# CONTROLSS_CTRL_CONTROLSS_CTRL register map
Vendor: Texas Instruments
Peripheral module from a debugger description file (folder AM263).
Registers are 8-bit, read-write, reset 0x0 unless marked. A register's access mark holds for its fields unless they carry their own. Offsets are as the file gives them; lines under a group give offsets from that group; [hi:lo] are bit positions; {n}, {i} and the like mark numbered series; 'fields as' and 'values as' point back to an identical list; <NAME> marks a mode.

## CONTROLSS_CTRL_CONTROLSS_CTRL
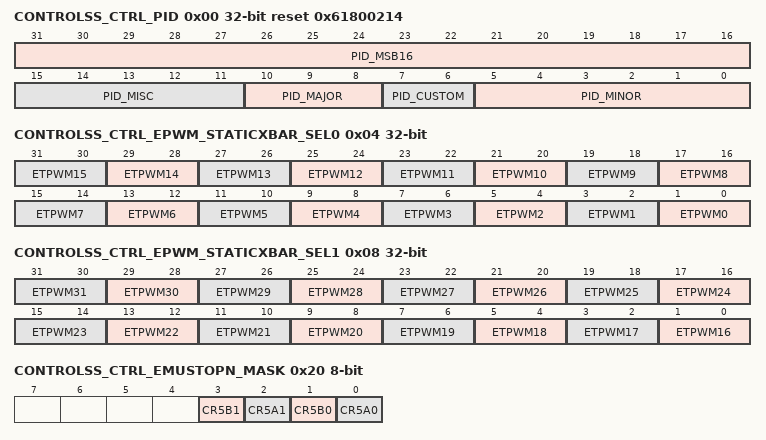
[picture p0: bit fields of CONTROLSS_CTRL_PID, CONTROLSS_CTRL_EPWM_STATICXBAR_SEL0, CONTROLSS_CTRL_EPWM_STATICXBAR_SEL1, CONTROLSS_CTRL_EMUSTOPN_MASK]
0x00 CONTROLSS_CTRL_PID 32-bit ro reset 0x61800214
  [31:16] PID_MSB16 — Not Defined
  [15:11] PID_MISC — Not Defined
  [10:8] PID_MAJOR — Not Defined
  [7:6] PID_CUSTOM — Not Defined
  [5:0] PID_MINOR — Not Defined
0x04 CONTROLSS_CTRL_EPWM_STATICXBAR_SEL0 32-bit
  [2n+1:2n] ETPWM{n} (n=0..15) — ETPWM{n} access from PCR grouping - 00 = G0, 01 = G1, 01 = G2, 11 = G3
0x08 CONTROLSS_CTRL_EPWM_STATICXBAR_SEL1 32-bit
  [2n-31:2n-32] ETPWM{n} (n=16..31) — ETPWM{n} access from PCR grouping - 00 = G0, 01 = G1, 01 = G2, 11 = G3
0x10 CONTROLSS_CTRL_EPWM_CLKSYNC 32-bit
  [31:0] BIT — ETPWM clock sync for each EPWM instance1: will allow CLK SYNC when GBCLKSYNC is written in0: No CLK SYNC when GBCLKSYNC is written in
0x18 CONTROLSS_CTRL_SDFM1_CLK0_SEL size not given
  [0] SEL — SDFM1 clock CK0 select0: source is SDFM1 CK0 from Pinmux1: source is SDFM0 CK0 from Pinmux
0x20 CONTROLSS_CTRL_EMUSTOPN_MASK
  [3] CR5B1 — Bit-mask for debug suspend cpu cores to EPWM0: CR5B1 enabled to control EMUSTOPn1: CR5B1 disabled to control EMUSTOPn
  [2] CR5A1 — Bit-mask for debug suspend cpu cores to EPWM0: CR5A1 enabled to control EMUSTOPn1: CR5A1 disabled to control EMUSTOPn
  [1] CR5B0 — Bit-mask for debug suspend cpu cores to EPWM0: CR5B0 enabled to control EMUSTOPn1: CR5B0 disabled to control EMUSTOPn
  [0] CR5A0 — Bit-mask for debug suspend cpu cores to EPWM0: CR5A0 enabled to control EMUSTOPn1: CR5A0 disabled to control EMUSTOPn
0x28 CONTROLSS_CTRL_CLB_AQ_EN0 32-bit
  [31:0] ENABLE — Enable ICCS control to CLB_AQ signal of PWM[15:0]
0x30 CONTROLSS_CTRL_CLB_AQ_EN1 32-bit
  [31:0] ENABLE — Enable ICCS control to CLB_AQ signal of PWM[31:16]
0x38 CONTROLSS_CTRL_CLB_DB_EN0 32-bit
  [31:0] ENABLE — Enable ICCS control to CLB_DB signal of PWM[15:0]
0x40 CONTROLSS_CTRL_CLB_DB_EN1 32-bit
  [31:0] ENABLE — Enable ICCS control to CLB_DB signal of PWM[31:16]
{0x100+4i} CONTROLSS_CTRL_ETPWM{i}_CLK_GATE (i=0..31)
  [2:0] CLK_GATE — writing '111' will gate clock for corresponding etpwm
{0x180+4i} CONTROLSS_CTRL_FSI_TX{i}_CLK_GATE (i=0..3)
  [2:0] CLK_GATE — writing '111' will gate clock for corresponding fsi_tx
{0x190+4i} CONTROLSS_CTRL_FSI_RX{i}_CLK_GATE (i=0..3)
  [2:0] CLK_GATE — writing '111' will gate clock for corresponding fsi_rx
{0x1A0+4i} CONTROLSS_CTRL_CMPSSA{i}_CLK_GATE (i=0..9)
  [2:0] CLK_GATE — writing '111' will gate clock for corresponding cmpss12b
{0x1D0+4i} CONTROLSS_CTRL_CMPSSB{i}_CLK_GATE (i=0..9)
  [2:0] CLK_GATE — writing '111' will gate clock for corresponding cmpss8b
{0x200+4i} CONTROLSS_CTRL_ECAP{i}_CLK_GATE (i=0..9)
  [2:0] CLK_GATE — writing '111' will gate clock for corresponding ecap
{0x240+4i} CONTROLSS_CTRL_EQEP{i}_CLK_GATE (i=0..2)
  [2:0] CLK_GATE — writing '111' will gate clock for corresponding eqep
0x250 CONTROLSS_CTRL_SDFM0_CLK_GATE
  [2:0] CLK_GATE — writing '111' will gate clock for corresponding sdfm
0x254 CONTROLSS_CTRL_SDFM1_CLK_GATE
  fields as CONTROLSS_CTRL_SDFM0_CLK_GATE
0x258 CONTROLSS_CTRL_DAC_CLK_GATE
  [2:0] CLK_GATE — writing '111' will gate clock for dac
{0x25C+4i} CONTROLSS_CTRL_ADC{i}_CLK_GATE (i=0..4)
  [2:0] CLK_GATE — writing '111' will gate clock for corresponding adc
{0x270+4i} CONTROLSS_CTRL_OTTO{i}_CLK_GATE (i=0..3)
  [2:0] CLK_GATE — writing '111' will gate clock for corresponding otto
0x280 CONTROLSS_CTRL_SDFM0_PLL_CLK_GATE
  [2:0] CLK_GATE — writing '111' will gate clock for corresponding sdfm pll clock
0x284 CONTROLSS_CTRL_SDFM1_PLL_CLK_GATE
  fields as CONTROLSS_CTRL_SDFM0_PLL_CLK_GATE
{0x288+4i} CONTROLSS_CTRL_FSI_TX{i}_PLL_CLK_GATE (i=0..3)
  [2:0] CLK_GATE — writing '111' will gate clock for corresponding fsi rx pll clock
{0x300+4i} CONTROLSS_CTRL_ETPWM{i}_RST (i=0..31)
  [2:0] RST — writing '111' will generate reset for corresponding etpwm
{0x380+4i} CONTROLSS_CTRL_FSI_TX{i}_RST (i=0..3)
  [2:0] RST — writing '111' will generate reset for corresponding fsi_tx
{0x390+4i} CONTROLSS_CTRL_FSI_RX{i}_RST (i=0..3)
  [2:0] RST — writing '111' will generate reset for corresponding fsi_rx
{0x3A0+4i} CONTROLSS_CTRL_CMPSSA{i}_RST (i=0..9)
  [2:0] RST — writing '111' will generate reset for corresponding cmpss12b
{0x3D0+4i} CONTROLSS_CTRL_CMPSSB{i}_RST (i=0..9)
  [2:0] RST — writing '111' will generate reset for corresponding cmpss8b
{0x400+4i} CONTROLSS_CTRL_ECAP{i}_RST (i=0..9)
  [2:0] RST — writing '111' will generate reset for corresponding ecap
{0x440+4i} CONTROLSS_CTRL_EQEP{i}_RST (i=0..2)
  [2:0] RST — writing '111' will generate reset for corresponding eqep
0x450 CONTROLSS_CTRL_SDFM0_RST
  [2:0] RST — writing '111' will generate reset for corresponding sdfm
0x454 CONTROLSS_CTRL_SDFM1_RST
  [2:0] RST — writing '111' will generate reset for corresponding sdfm
0x458 CONTROLSS_CTRL_DAC_RST
  [2:0] RST — writing '111' will generate reset for dac
{0x45C+4i} CONTROLSS_CTRL_ADC{i}_RST (i=0..4)
  [2:0] RST — writing '111' will generate reset for corresponding adc
{0x470+4i} CONTROLSS_CTRL_OTTO{i}_RST (i=0..3)
  [2:0] RST — writing '111' will generate reset for corresponding otto
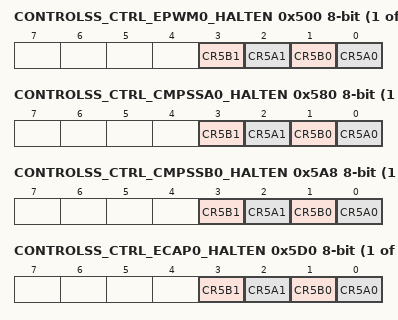
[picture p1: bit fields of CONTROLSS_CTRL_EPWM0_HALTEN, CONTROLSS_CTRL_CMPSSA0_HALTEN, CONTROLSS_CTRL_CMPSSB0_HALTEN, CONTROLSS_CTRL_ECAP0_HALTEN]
{0x500+4i} CONTROLSS_CTRL_EPWM{i}_HALTEN (i=0..31)
  [3] CR5B1 — 1'b0: IP Halt disabled with corresponding CPU halt1'b1: IP Halt enabled with corresponding CPU halt
  [2] CR5A1 — 1'b0: IP Halt disabled with corresponding CPU halt1'b1: IP Halt enabled with corresponding CPU halt
  [1] CR5B0 — 1'b0: IP Halt disabled with corresponding CPU halt1'b1: IP Halt enabled with corresponding CPU halt
  [0] CR5A0 — 1'b0: IP Halt disabled with corresponding CPU halt1'b1: IP Halt enabled with corresponding CPU halt
{0x580+4i} CONTROLSS_CTRL_CMPSSA{i}_HALTEN (i=0..9)
  fields as CONTROLSS_CTRL_EPWM0_HALTEN
{0x5A8+4i} CONTROLSS_CTRL_CMPSSB{i}_HALTEN (i=0..9)
  fields as CONTROLSS_CTRL_EPWM0_HALTEN
{0x5D0+4i} CONTROLSS_CTRL_ECAP{i}_HALTEN (i=0..9)
  fields as CONTROLSS_CTRL_EPWM0_HALTEN
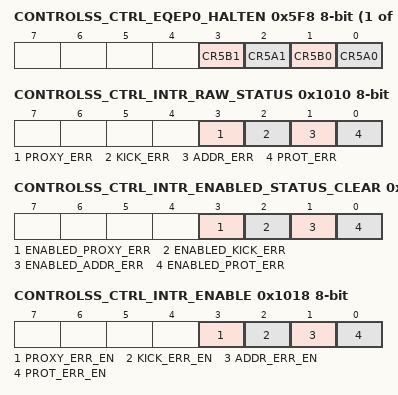
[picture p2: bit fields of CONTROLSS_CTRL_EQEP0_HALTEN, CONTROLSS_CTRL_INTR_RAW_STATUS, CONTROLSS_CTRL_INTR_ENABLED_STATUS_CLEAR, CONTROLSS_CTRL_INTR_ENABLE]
{0x5F8+4i} CONTROLSS_CTRL_EQEP{i}_HALTEN (i=0..2)
  fields as CONTROLSS_CTRL_EPWM0_HALTEN
0x1008 CONTROLSS_CTRL_LOCK0_KICK0 32-bit
  [31:0] LOCK0_KICK0 — - KICK0 component
0x100C CONTROLSS_CTRL_LOCK0_KICK1 32-bit
  [31:0] LOCK0_KICK1 — - KICK1 component
0x1010 CONTROLSS_CTRL_INTR_RAW_STATUS
  [3] PROXY_ERR — Proxy0 access violation error. Raw status is read. Write a 1 to set the status. Writing a 0 has no effect.
  [2] KICK_ERR — Kick access violation error. Raw status is read. Write a 1 to set the status. Writing a 0 has no effect.
  [1] ADDR_ERR — Addressing violation error. Raw status is read. Write a 1 to set the status. Writing a 0 has no effect.
  [0] PROT_ERR — Protection violation error. Raw status is read. Write a 1 to set the status. Writing a 0 has no effect.
0x1014 CONTROLSS_CTRL_INTR_ENABLED_STATUS_CLEAR
  [3] ENABLED_PROXY_ERR — Proxy0 access violation error. Enabled status is read. Write a 1 to clear the status. Writing a 0 has no effect.
  [2] ENABLED_KICK_ERR — Kick access violation error. Enabled status is read. Write a 1 to clear the status. Writing a 0 has no effect.
  [1] ENABLED_ADDR_ERR — Addressing violation error. Enabled status is read. Write a 1 to clear the status. Writing a 0 has no effect.
  [0] ENABLED_PROT_ERR — Protection violation error. Enabled status is read. Write a 1 to clear the status. Writing a 0 has no effect.
0x1018 CONTROLSS_CTRL_INTR_ENABLE
  [3] PROXY_ERR_EN — Proxy0 access violation error enable. Write a 1 to set the enable. Writing a 0 has no effect.
  [2] KICK_ERR_EN — Kick access violation error enable. Write a 1 to set the enable. Writing a 0 has no effect.
  [1] ADDR_ERR_EN — Addressing violation error enable. Write a 1 to set the enable. Writing a 0 has no effect.
  [0] PROT_ERR_EN — Protection violation error enable. Write a 1 to set the enable. Writing a 0 has no effect.
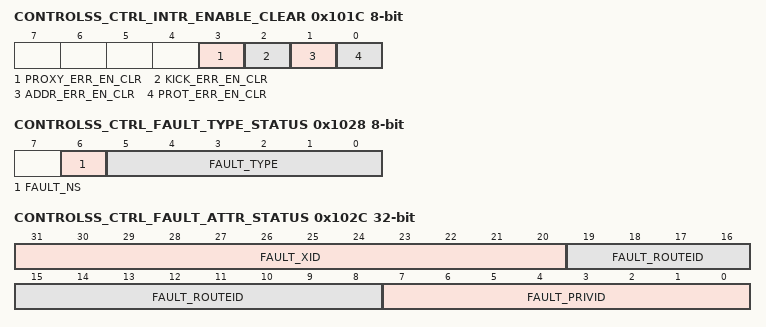
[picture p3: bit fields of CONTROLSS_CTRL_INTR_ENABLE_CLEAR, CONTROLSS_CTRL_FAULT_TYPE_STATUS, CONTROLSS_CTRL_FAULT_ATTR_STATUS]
0x101C CONTROLSS_CTRL_INTR_ENABLE_CLEAR
  [3] PROXY_ERR_EN_CLR — Proxy0 access violation error enable clear. Write a 1 to clear the enable. Writing a 0 has no effect.
  [2] KICK_ERR_EN_CLR — Kick access violation error enable clear. Write a 1 to clear the enable. Writing a 0 has no effect.
  [1] ADDR_ERR_EN_CLR — Addressing violation error enable clear. Write a 1 to clear the enable. Writing a 0 has no effect.
  [0] PROT_ERR_EN_CLR — Protection violation error enable clear. Write a 1 to clear the enable. Writing a 0 has no effect.
0x1020 CONTROLSS_CTRL_EOI
  [7:0] EOI_VECTOR — EOI vector value. Write this with interrupt distribution value in the chip.
0x1024 CONTROLSS_CTRL_FAULT_ADDRESS 32-bit ro
  [31:0] FAULT_ADDR — Fault Address.
0x1028 CONTROLSS_CTRL_FAULT_TYPE_STATUS ro
  [6] FAULT_NS — Non-secure access.
  [5:0] FAULT_TYPE — Fault Type 10_0000 = Supervisor read fault - priv = 1 dir = 1 dtype != 1 01_0000 = Supervisor write fault - priv = 1 dir = 0 00_1000 = Supervisor execute fault - priv = 1 dir = 1 dtype = 1 00_0100 = User read fault - priv = 0 dir = 1 dtype = 1 00_0010 = User write fault - priv = 0 dir = 0 00_0001 = User execute fault - priv = 0 dir = 1 dtype = 1 00_0000 = No fault
0x102C CONTROLSS_CTRL_FAULT_ATTR_STATUS 32-bit ro
  [31:20] FAULT_XID — XID.
  [19:8] FAULT_ROUTEID — Route ID.
  [7:0] FAULT_PRIVID — Privilege ID.
0x1030 CONTROLSS_CTRL_FAULT_CLEAR size not given wo
  [0] FAULT_CLR — Fault clear. Writing a 1 clears the current fault. Writing a 0 has no effect.
